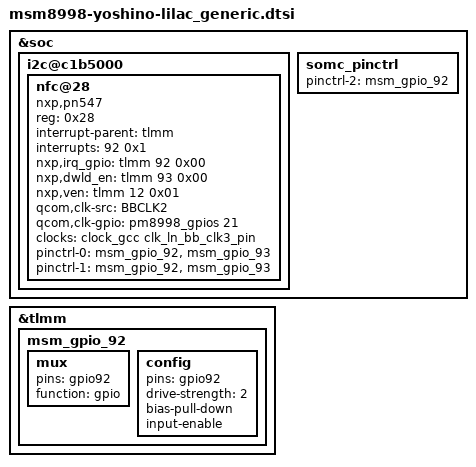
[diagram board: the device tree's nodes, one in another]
/* arch/arm64/boot/dts/qcom/msm8998-lilac_generic.dtsi
 *
 * This program is free software; you can redistribute it and/or modify
 * it under the terms of the GNU General Public License version 2 and
 * only version 2 as published by the Free Software Foundation.
 *
 * This program is distributed in the hope that it will be useful,
 * but WITHOUT ANY WARRANTY; without even the implied warranty of
 * MERCHANTABILITY or FITNESS FOR A PARTICULAR PURPOSE.  See the
 * GNU General Public License for more details.
 */
/*
 * Copyright (C) 2016 Sony Mobile Communications Inc.
 *
 * This program is free software; you can redistribute it and/or modify
 * it under the terms of the GNU General Public License version 2, as
 * published by the Free Software Foundation.
 */

#include "msm8998-yoshino-lilac_common.dtsi"

&soc {
	/* I2C : BLSP7 */
	i2c@c1b5000 { /* BLSP2 QUP1 */
		nfc@28 {
			compatible = "nxp,pn547";
			reg = <0x28>;
			interrupt-parent = <&tlmm>;
			interrupts = <92 0x1>;
			nxp,irq_gpio = <&tlmm 92 0x00>;
			nxp,dwld_en = <&tlmm 93 0x00>;
			nxp,ven = <&tlmm 12 0x01>;
			qcom,clk-src = "BBCLK2";
			qcom,clk-gpio = <&pm8998_gpios 21 0x00>;
			clocks = <&clock_gcc clk_ln_bb_clk3_pin>;
			clock-names = "nfc_clk";
			pinctrl-names = "pn547-active", "pn547-inactive";
			pinctrl-0 = <&msm_gpio_92 &msm_gpio_93>;
			pinctrl-1 = <&msm_gpio_92 &msm_gpio_93>;
		};
	};
	somc_pinctrl: somc_pinctrl {
		/* If variant specific default setting is needed,
		   fill pinctrl-2 value in <variant>.dtsi */
		pinctrl-2 = <&msm_gpio_92>;
	};
};

&tlmm {
	/* GPIO_92 : NFC_IRQ_FELICA_INT_N */
	msm_gpio_92: msm_gpio_92 {
		mux {
			pins = "gpio92";
			function = "gpio";
		};

		config {
			pins = "gpio92";
			drive-strength = <2>;
			bias-pull-down;
			input-enable;
		};
	};
};
